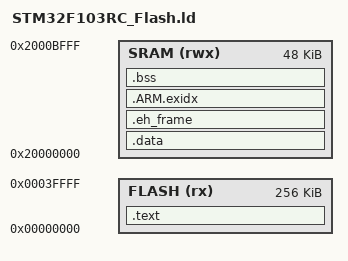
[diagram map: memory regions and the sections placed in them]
/* Copyright (c) 2006-2012 MIS Institute of the HEIG affiliated to the University of
** Applied Sciences of Western Switzerland. All rights reserved.
** IN NO EVENT SHALL THE MIS INSTITUTE NOR THE HEIG NOR THE UNIVERSITY OF APPLIED
** SCIENCES OF WESTERN SWITZERLAND BE LIABLE TO ANY PARTY FOR DIRECT, INDIRECT, SPECIAL,
** INCIDENTAL, OR CONSEQUENTIAL DAMAGES ARISING OUT OF THE USE OF THIS SOFTWARE AND ITS
** DOCUMENTATION, EVEN IF THE MIS INSTITUTE OR THE HEIG OR THE UNIVERSITY OF APPLIED
** SCIENCES OF WESTERN SWITZERLAND HAS BEEN ADVISED OF THE POSSIBILITY OF SUCH DAMAGE.
** THE MIS INSTITUTE, THE HEIG AND THE UNIVERSITY OF APPLIED SCIENCES OF WESTERN SWIT-
** ZERLAND SPECIFICALLY DISCLAIMS ANY WARRANTIES, INCLUDING, BUT NOT LIMITED TO, THE
** IMPLIED WARRANTIES OF MERCHANTABILITY AND FITNESS FOR A PARTICULAR PURPOSE. THE SOFT-
** WARE PROVIDED HEREUNDER IS ON AN "AS IS" BASIS, AND THE MIS INSTITUTE NOR THE HEIG
** AND NOR THE UNIVERSITY OF APPLIED SCIENCES OF WESTERN SWITZERLAND HAVE NO OBLIGATION
** TO PROVIDE MAINTENANCE, SUPPORT, UPDATES, ENHANCEMENTS, OR MODIFICATIONS.
*/
/* ZOTTAOS_CortexM3_STM32F103RC_Flash.ld: 
** Version identifier: January 2012
** Compiler and linker: 
** Authors: MIS-TIC 
*/
ENTRY(_OSResetHandler)

SDRAM_START = 0x20000000;
SDRAM_SIZE  = 0x0000C000;

MAIN_ALLOCA_SIZE = 0x1000;

_OSStartStack = SDRAM_START + SDRAM_SIZE;
_OSStartMainStack = _OSStartStack - MAIN_ALLOCA_SIZE;

MEMORY
{
    FLASH (rx) : ORIGIN = 0x00000000, LENGTH = 256K
    SRAM (rwx) : ORIGIN = 0x20000000, LENGTH = 48K
}

SECTIONS
{
    .text :
    {
        KEEP(*(.isr_vector_general))  /* Cortex-M3 vector table */
        KEEP(*(.isr_vector_specific)) /* STM32 specific vector table */
        *(.text*)
        *(.rodata*)
        _etext = .;
    } > FLASH

    .data : AT (ADDR(.text) + SIZEOF(.text))
    {
        _data = .;
        *(vtable)
        *(.data*)
        _edata = .;
    } > SRAM

    .eh_frame :
    {
        KEEP (*(.eh_frame))
    } > SRAM

    .ARM.exidx :
    {
        *(.ARM.exidx* .gnu.linkonce.armexidx.*)
    } > SRAM
    
    .bss :
    {
        _bss = .;
        *(.bss*)
        *(COMMON)
        _ebss = .;
        . = ALIGN(4);
        _heap = .;
    } > SRAM
}
